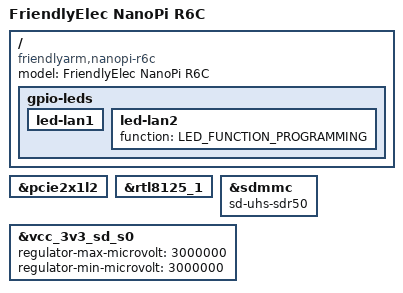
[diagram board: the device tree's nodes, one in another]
// SPDX-License-Identifier: GPL-2.0-or-later OR MIT

/dts-v1/;
#include "rk3588s-nanopi-r6s.dts"

/ {
	model = "FriendlyElec NanoPi R6C";
	compatible = "friendlyarm,nanopi-r6c", "rockchip,rk3588";

	gpio-leds {
		led-lan1 {
			/delete-property/ function-enumerator;
		};

		led-lan2 {
			/delete-property/ function-enumerator;
			function = LED_FUNCTION_PROGRAMMING;
		};
	};
};

&pcie2x1l2 {
	/delete-node/ pcie@0,0;
};

&rtl8125_1 {
	/delete-property/ label;
};

/* Keep R6C's existing SD settings when including the R6S device tree. */
&sdmmc {
	/delete-property/ sd-uhs-sdr104;
	sd-uhs-sdr50;
};

&vcc_3v3_sd_s0 {
	regulator-max-microvolt = <3000000>;
	regulator-min-microvolt = <3000000>;
};
